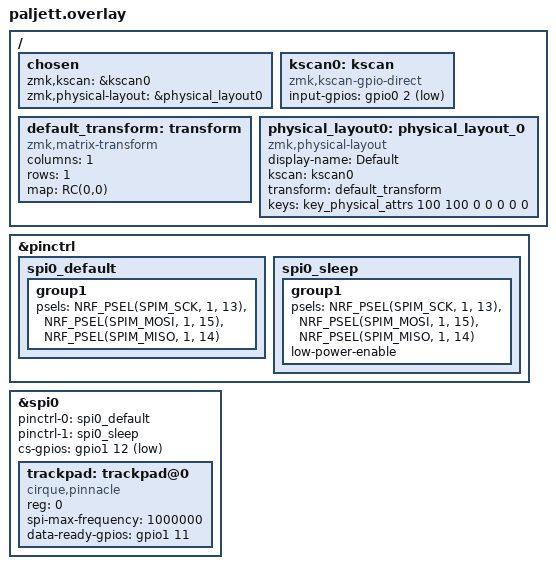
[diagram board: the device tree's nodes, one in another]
#include <dt-bindings/zmk/matrix_transform.h>
#include <physical_layouts.dtsi>

/ {
    chosen {
        zmk,kscan = &kscan0;
        zmk,physical-layout = &physical_layout0;
    };

    kscan0: kscan {
        compatible = "zmk,kscan-gpio-direct";
        input-gpios = <&gpio0 2 (GPIO_ACTIVE_LOW | GPIO_PULL_UP)>;
    };

    default_transform: transform {
        compatible = "zmk,matrix-transform";
        columns = <1>;
        rows = <1>;
        map = <RC(0,0)>;
    };

    physical_layout0: physical_layout_0 {
        compatible = "zmk,physical-layout";
        display-name = "Default";
        kscan = <&kscan0>;
        transform = <&default_transform>;
        keys = <&key_physical_attrs 100 100 0 0 0 0 0>;
    };
};

&pinctrl {
    spi0_default: spi0_default {
        group1 {
            psels = <NRF_PSEL(SPIM_SCK, 1, 13)>, <NRF_PSEL(SPIM_MOSI, 1, 15)>, <NRF_PSEL(SPIM_MISO, 1, 14)>;
        };
    };
    spi0_sleep: spi0_sleep {
        group1 {
            psels = <NRF_PSEL(SPIM_SCK, 1, 13)>, <NRF_PSEL(SPIM_MOSI, 1, 15)>, <NRF_PSEL(SPIM_MISO, 1, 14)>;
            low-power-enable;
        };
    };
};

&spi0 {
    status = "okay";
    pinctrl-0 = <&spi0_default>;
    pinctrl-1 = <&spi0_sleep>;
    pinctrl-names = "default", "sleep";
    cs-gpios = <&gpio1 12 GPIO_ACTIVE_LOW>;

    trackpad: trackpad@0 {
        compatible = "cirque,pinnacle";
        reg = <0>;
        spi-max-frequency = <1000000>;
        data-ready-gpios = <&gpio1 11 GPIO_ACTIVE_HIGH>;
    };
};
